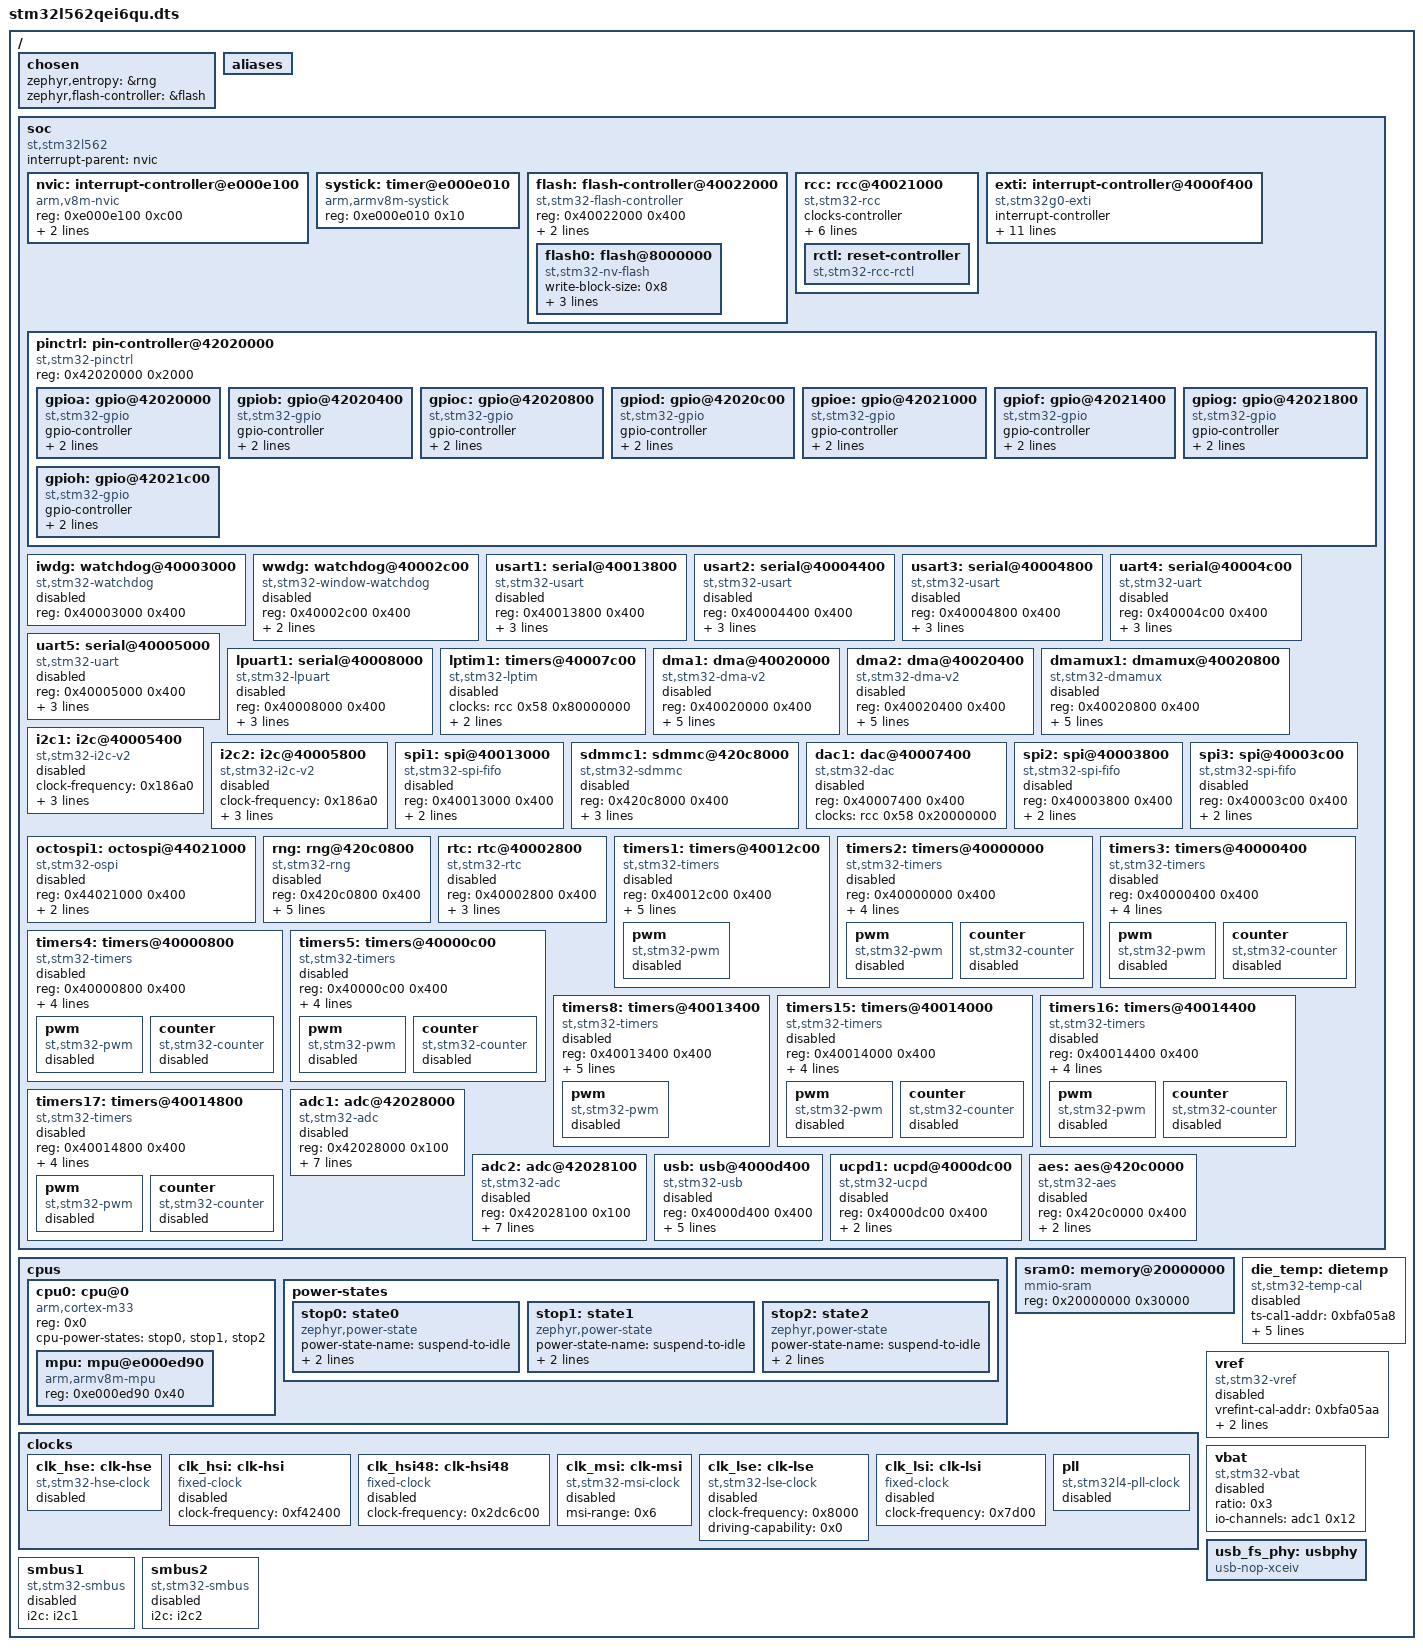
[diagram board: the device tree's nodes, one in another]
/dts-v1/;

/ {
	#address-cells = < 0x1 >;
	#size-cells = < 0x1 >;
	chosen {
		zephyr,entropy = &rng;
		zephyr,flash-controller = &flash;
	};
	aliases {
	};
	soc {
		#address-cells = < 0x1 >;
		#size-cells = < 0x1 >;
		compatible = "st,stm32l562", "st,stm32l5", "simple-bus";
		interrupt-parent = < &nvic >;
		ranges;
		nvic: interrupt-controller@e000e100 {
			#address-cells = < 0x1 >;
			compatible = "arm,v8m-nvic";
			reg = < 0xe000e100 0xc00 >;
			interrupt-controller;
			#interrupt-cells = < 0x2 >;
			arm,num-irq-priority-bits = < 0x3 >;
			phandle = < 0x1 >;
		};
		systick: timer@e000e010 {
			compatible = "arm,armv8m-systick";
			reg = < 0xe000e010 0x10 >;
		};
		flash: flash-controller@40022000 {
			compatible = "st,stm32-flash-controller", "st,stm32l5-flash-controller";
			reg = < 0x40022000 0x400 >;
			interrupts = < 0x6 0x0 >;
			clocks = < &rcc 0x48 0x100 >;
			#address-cells = < 0x1 >;
			#size-cells = < 0x1 >;
			flash0: flash@8000000 {
				compatible = "st,stm32-nv-flash", "soc-nv-flash";
				write-block-size = < 0x8 >;
				erase-block-size = < 0x800 >;
				max-erase-time = < 0x19 >;
				reg = < 0x8000000 0x80000 >;
			};
		};
		rcc: rcc@40021000 {
			compatible = "st,stm32-rcc";
			clocks-controller;
			#clock-cells = < 0x2 >;
			reg = < 0x40021000 0x400 >;
			undershoot-prevention;
			clock-frequency = < 0x1 >;
			ahb-prescaler = < 0x1 >;
			apb1-prescaler = < 0x1 >;
			apb2-prescaler = < 0x1 >;
			phandle = < 0x2 >;
			rctl: reset-controller {
				compatible = "st,stm32-rcc-rctl";
				#reset-cells = < 0x1 >;
				phandle = < 0x3 >;
			};
		};
		exti: interrupt-controller@4000f400 {
			compatible = "st,stm32g0-exti", "st,stm32-exti";
			interrupt-controller;
			#interrupt-cells = < 0x1 >;
			reg = < 0x4000f400 0x400 >;
			num-lines = < 0x10 >;
			interrupts = < 0xb 0x0 >, < 0xc 0x0 >, < 0xd 0x0 >, < 0xe 0x0 >, < 0xf 0x0 >, < 0x10 0x0 >, < 0x11 0x0 >, < 0x12 0x0 >, < 0x13 0x0 >, < 0x14 0x0 >, < 0x15 0x0 >, < 0x16 0x0 >, < 0x17 0x0 >, < 0x18 0x0 >, < 0x19 0x0 >, < 0x1a 0x0 >;
			interrupt-names = "line0", "line1", "line2", "line3", "line4", "line5", "line6", "line7", "line8", "line9", "line10", "line11", "line12", "line13", "line14", "line15";
			line-ranges = < 0x0 0x1 >, < 0x1 0x1 >, < 0x2 0x1 >, < 0x3 0x1 >, < 0x4 0x1 >, < 0x5 0x1 >, < 0x6 0x1 >, < 0x7 0x1 >, < 0x8 0x1 >, < 0x9 0x1 >, < 0xa 0x1 >, < 0xb 0x1 >, < 0xc 0x1 >, < 0xd 0x1 >, < 0xe 0x1 >, < 0xf 0x1 >;
		};
		pinctrl: pin-controller@42020000 {
			compatible = "st,stm32-pinctrl";
			#address-cells = < 0x1 >;
			#size-cells = < 0x1 >;
			reg = < 0x42020000 0x2000 >;
			gpioa: gpio@42020000 {
				compatible = "st,stm32-gpio";
				gpio-controller;
				#gpio-cells = < 0x2 >;
				reg = < 0x42020000 0x400 >;
				clocks = < &rcc 0x4c 0x1 >;
			};
			gpiob: gpio@42020400 {
				compatible = "st,stm32-gpio";
				gpio-controller;
				#gpio-cells = < 0x2 >;
				reg = < 0x42020400 0x400 >;
				clocks = < &rcc 0x4c 0x2 >;
			};
			gpioc: gpio@42020800 {
				compatible = "st,stm32-gpio";
				gpio-controller;
				#gpio-cells = < 0x2 >;
				reg = < 0x42020800 0x400 >;
				clocks = < &rcc 0x4c 0x4 >;
			};
			gpiod: gpio@42020c00 {
				compatible = "st,stm32-gpio";
				gpio-controller;
				#gpio-cells = < 0x2 >;
				reg = < 0x42020c00 0x400 >;
				clocks = < &rcc 0x4c 0x8 >;
			};
			gpioe: gpio@42021000 {
				compatible = "st,stm32-gpio";
				gpio-controller;
				#gpio-cells = < 0x2 >;
				reg = < 0x42021000 0x400 >;
				clocks = < &rcc 0x4c 0x10 >;
			};
			gpiof: gpio@42021400 {
				compatible = "st,stm32-gpio";
				gpio-controller;
				#gpio-cells = < 0x2 >;
				reg = < 0x42021400 0x400 >;
				clocks = < &rcc 0x4c 0x20 >;
			};
			gpiog: gpio@42021800 {
				compatible = "st,stm32-gpio";
				gpio-controller;
				#gpio-cells = < 0x2 >;
				reg = < 0x42021800 0x400 >;
				clocks = < &rcc 0x4c 0x40 >;
			};
			gpioh: gpio@42021c00 {
				compatible = "st,stm32-gpio";
				gpio-controller;
				#gpio-cells = < 0x2 >;
				reg = < 0x42021c00 0x400 >;
				clocks = < &rcc 0x4c 0x80 >;
			};
		};
		iwdg: watchdog@40003000 {
			compatible = "st,stm32-watchdog";
			reg = < 0x40003000 0x400 >;
			status = "disabled";
		};
		wwdg: watchdog@40002c00 {
			compatible = "st,stm32-window-watchdog";
			reg = < 0x40002c00 0x400 >;
			clocks = < &rcc 0x58 0x800 >;
			interrupts = < 0x0 0x6 >;
			status = "disabled";
		};
		usart1: serial@40013800 {
			compatible = "st,stm32-usart", "st,stm32-uart";
			reg = < 0x40013800 0x400 >;
			clocks = < &rcc 0x60 0x4000 >;
			resets = < &rctl 0x80e >;
			interrupts = < 0x3d 0x0 >;
			status = "disabled";
		};
		usart2: serial@40004400 {
			compatible = "st,stm32-usart", "st,stm32-uart";
			reg = < 0x40004400 0x400 >;
			clocks = < &rcc 0x58 0x20000 >;
			resets = < &rctl 0x711 >;
			interrupts = < 0x3e 0x0 >;
			status = "disabled";
		};
		usart3: serial@40004800 {
			compatible = "st,stm32-usart", "st,stm32-uart";
			reg = < 0x40004800 0x400 >;
			clocks = < &rcc 0x58 0x40000 >;
			resets = < &rctl 0x712 >;
			interrupts = < 0x3f 0x0 >;
			status = "disabled";
		};
		uart4: serial@40004c00 {
			compatible = "st,stm32-uart";
			reg = < 0x40004c00 0x400 >;
			clocks = < &rcc 0x58 0x80000 >;
			resets = < &rctl 0x713 >;
			interrupts = < 0x40 0x0 >;
			status = "disabled";
		};
		uart5: serial@40005000 {
			compatible = "st,stm32-uart";
			reg = < 0x40005000 0x400 >;
			clocks = < &rcc 0x58 0x100000 >;
			resets = < &rctl 0x714 >;
			interrupts = < 0x41 0x0 >;
			status = "disabled";
		};
		lpuart1: serial@40008000 {
			compatible = "st,stm32-lpuart", "st,stm32-uart";
			reg = < 0x40008000 0x400 >;
			clocks = < &rcc 0x5c 0x1 >;
			resets = < &rctl 0x780 >;
			interrupts = < 0x42 0x0 >;
			status = "disabled";
		};
		lptim1: timers@40007c00 {
			compatible = "st,stm32-lptim";
			clocks = < &rcc 0x58 0x80000000 >;
			#address-cells = < 0x1 >;
			#size-cells = < 0x0 >;
			reg = < 0x40007c00 0x400 >;
			interrupts = < 0x43 0x1 >;
			interrupt-names = "wakeup";
			status = "disabled";
		};
		dma1: dma@40020000 {
			compatible = "st,stm32-dma-v2";
			#dma-cells = < 0x3 >;
			reg = < 0x40020000 0x400 >;
			interrupts = < 0x1d 0x0 0x1e 0x0 0x1f 0x0 0x20 0x0 0x21 0x0 0x22 0x0 0x23 0x0 0x24 0x0 >;
			clocks = < &rcc 0x48 0x1 >;
			dma-requests = < 0x8 >;
			dma-offset = < 0x0 >;
			status = "disabled";
		};
		dma2: dma@40020400 {
			compatible = "st,stm32-dma-v2";
			#dma-cells = < 0x3 >;
			reg = < 0x40020400 0x400 >;
			interrupts = < 0x50 0x0 0x51 0x0 0x52 0x0 0x53 0x0 0x54 0x0 0x55 0x0 0x56 0x0 0x57 0x0 >;
			clocks = < &rcc 0x48 0x2 >;
			dma-requests = < 0x8 >;
			dma-offset = < 0x8 >;
			status = "disabled";
		};
		dmamux1: dmamux@40020800 {
			compatible = "st,stm32-dmamux";
			#dma-cells = < 0x3 >;
			reg = < 0x40020800 0x400 >;
			interrupts = < 0x1b 0x0 >;
			clocks = < &rcc 0x48 0x4 >;
			dma-channels = < 0x10 >;
			dma-generators = < 0x4 >;
			dma-requests = < 0x5a >;
			status = "disabled";
		};
		i2c1: i2c@40005400 {
			compatible = "st,stm32-i2c-v2";
			clock-frequency = < 0x186a0 >;
			#address-cells = < 0x1 >;
			#size-cells = < 0x0 >;
			reg = < 0x40005400 0x400 >;
			clocks = < &rcc 0x58 0x200000 >;
			interrupts = < 0x37 0x0 >, < 0x38 0x0 >;
			interrupt-names = "event", "error";
			status = "disabled";
			phandle = < 0x9 >;
		};
		i2c2: i2c@40005800 {
			compatible = "st,stm32-i2c-v2";
			#address-cells = < 0x1 >;
			#size-cells = < 0x0 >;
			clock-frequency = < 0x186a0 >;
			reg = < 0x40005800 0x400 >;
			clocks = < &rcc 0x58 0x400000 >;
			interrupts = < 0x39 0x0 >, < 0x3a 0x0 >;
			interrupt-names = "event", "error";
			status = "disabled";
			phandle = < 0xa >;
		};
		spi1: spi@40013000 {
			compatible = "st,stm32-spi-fifo", "st,stm32-spi";
			#address-cells = < 0x1 >;
			#size-cells = < 0x0 >;
			reg = < 0x40013000 0x400 >;
			interrupts = < 0x3b 0x5 >;
			clocks = < &rcc 0x60 0x1000 >;
			status = "disabled";
		};
		sdmmc1: sdmmc@420c8000 {
			compatible = "st,stm32-sdmmc";
			reg = < 0x420c8000 0x400 >;
			clocks = < &rcc 0x4c 0x400000 >, < &rcc 0x2 0x2e9c >;
			resets = < &rctl 0x596 >;
			interrupts = < 0x4e 0x0 >;
			status = "disabled";
		};
		dac1: dac@40007400 {
			compatible = "st,stm32-dac";
			reg = < 0x40007400 0x400 >;
			clocks = < &rcc 0x58 0x20000000 >;
			status = "disabled";
			#io-channel-cells = < 0x1 >;
		};
		spi2: spi@40003800 {
			compatible = "st,stm32-spi-fifo", "st,stm32-spi";
			#address-cells = < 0x1 >;
			#size-cells = < 0x0 >;
			reg = < 0x40003800 0x400 >;
			interrupts = < 0x3c 0x5 >;
			clocks = < &rcc 0x58 0x4000 >;
			status = "disabled";
		};
		spi3: spi@40003c00 {
			compatible = "st,stm32-spi-fifo", "st,stm32-spi";
			#address-cells = < 0x1 >;
			#size-cells = < 0x0 >;
			reg = < 0x40003c00 0x400 >;
			interrupts = < 0x63 0x5 >;
			clocks = < &rcc 0x58 0x8000 >;
			status = "disabled";
		};
		octospi1: octospi@44021000 {
			compatible = "st,stm32-ospi";
			reg = < 0x44021000 0x400 >;
			interrupts = < 0x4c 0x0 >;
			clock-names = "ospix", "ospi-ker";
			clocks = < &rcc 0x50 0x100 >, < &rcc 0x6 0x749c >;
			#address-cells = < 0x1 >;
			#size-cells = < 0x0 >;
			status = "disabled";
		};
		rng: rng@420c0800 {
			compatible = "st,stm32-rng";
			reg = < 0x420c0800 0x400 >;
			interrupts = < 0x5e 0x0 >;
			clocks = < &rcc 0x4c 0x40000 >;
			nist-config = < 0xf00d00 >;
			health-test-magic = < 0x17590abc >;
			health-test-config = < 0xa2b3 >;
			status = "disabled";
		};
		rtc: rtc@40002800 {
			compatible = "st,stm32-rtc";
			reg = < 0x40002800 0x400 >;
			interrupts = < 0x2 0x0 >;
			clocks = < &rcc 0x58 0x400 >;
			prescaler = < 0x8000 >;
			status = "disabled";
		};
		timers1: timers@40012c00 {
			compatible = "st,stm32-timers";
			reg = < 0x40012c00 0x400 >;
			clocks = < &rcc 0x60 0x800 >;
			resets = < &rctl 0x80b >;
			interrupts = < 0x29 0x0 >, < 0x2a 0x0 >, < 0x2b 0x0 >, < 0x2c 0x0 >;
			interrupt-names = "brk", "up", "trgcom", "cc";
			st,prescaler = < 0x0 >;
			status = "disabled";
			pwm {
				compatible = "st,stm32-pwm";
				status = "disabled";
				#pwm-cells = < 0x3 >;
			};
		};
		timers2: timers@40000000 {
			compatible = "st,stm32-timers";
			reg = < 0x40000000 0x400 >;
			clocks = < &rcc 0x58 0x1 >;
			resets = < &rctl 0x700 >;
			interrupts = < 0x2d 0x0 >;
			interrupt-names = "global";
			st,prescaler = < 0x0 >;
			status = "disabled";
			pwm {
				compatible = "st,stm32-pwm";
				status = "disabled";
				#pwm-cells = < 0x3 >;
			};
			counter {
				compatible = "st,stm32-counter";
				status = "disabled";
			};
		};
		timers3: timers@40000400 {
			compatible = "st,stm32-timers";
			reg = < 0x40000400 0x400 >;
			clocks = < &rcc 0x58 0x2 >;
			resets = < &rctl 0x701 >;
			interrupts = < 0x2e 0x0 >;
			interrupt-names = "global";
			st,prescaler = < 0x0 >;
			status = "disabled";
			pwm {
				compatible = "st,stm32-pwm";
				status = "disabled";
				#pwm-cells = < 0x3 >;
			};
			counter {
				compatible = "st,stm32-counter";
				status = "disabled";
			};
		};
		timers4: timers@40000800 {
			compatible = "st,stm32-timers";
			reg = < 0x40000800 0x400 >;
			clocks = < &rcc 0x58 0x4 >;
			resets = < &rctl 0x702 >;
			interrupts = < 0x2f 0x0 >;
			interrupt-names = "global";
			st,prescaler = < 0x0 >;
			status = "disabled";
			pwm {
				compatible = "st,stm32-pwm";
				status = "disabled";
				#pwm-cells = < 0x3 >;
			};
			counter {
				compatible = "st,stm32-counter";
				status = "disabled";
			};
		};
		timers5: timers@40000c00 {
			compatible = "st,stm32-timers";
			reg = < 0x40000c00 0x400 >;
			clocks = < &rcc 0x58 0x8 >;
			resets = < &rctl 0x703 >;
			interrupts = < 0x30 0x0 >;
			interrupt-names = "global";
			st,prescaler = < 0x0 >;
			status = "disabled";
			pwm {
				compatible = "st,stm32-pwm";
				status = "disabled";
				#pwm-cells = < 0x3 >;
			};
			counter {
				compatible = "st,stm32-counter";
				status = "disabled";
			};
		};
		timers8: timers@40013400 {
			compatible = "st,stm32-timers";
			reg = < 0x40013400 0x400 >;
			clocks = < &rcc 0x60 0x2000 >;
			resets = < &rctl 0x80d >;
			interrupts = < 0x33 0x0 >, < 0x34 0x0 >, < 0x35 0x0 >, < 0x36 0x0 >;
			interrupt-names = "brk", "up", "trgcom", "cc";
			st,prescaler = < 0x0 >;
			status = "disabled";
			pwm {
				compatible = "st,stm32-pwm";
				status = "disabled";
				#pwm-cells = < 0x3 >;
			};
		};
		timers15: timers@40014000 {
			compatible = "st,stm32-timers";
			reg = < 0x40014000 0x400 >;
			clocks = < &rcc 0x60 0x10000 >;
			resets = < &rctl 0x810 >;
			interrupts = < 0x45 0x0 >;
			interrupt-names = "global";
			st,prescaler = < 0x0 >;
			status = "disabled";
			pwm {
				compatible = "st,stm32-pwm";
				status = "disabled";
				#pwm-cells = < 0x3 >;
			};
			counter {
				compatible = "st,stm32-counter";
				status = "disabled";
			};
		};
		timers16: timers@40014400 {
			compatible = "st,stm32-timers";
			reg = < 0x40014400 0x400 >;
			clocks = < &rcc 0x60 0x20000 >;
			resets = < &rctl 0x811 >;
			interrupts = < 0x46 0x0 >;
			interrupt-names = "global";
			st,prescaler = < 0x0 >;
			status = "disabled";
			pwm {
				compatible = "st,stm32-pwm";
				status = "disabled";
				#pwm-cells = < 0x3 >;
			};
			counter {
				compatible = "st,stm32-counter";
				status = "disabled";
			};
		};
		timers17: timers@40014800 {
			compatible = "st,stm32-timers";
			reg = < 0x40014800 0x400 >;
			clocks = < &rcc 0x60 0x40000 >;
			resets = < &rctl 0x812 >;
			interrupts = < 0x47 0x0 >;
			interrupt-names = "global";
			st,prescaler = < 0x0 >;
			status = "disabled";
			pwm {
				compatible = "st,stm32-pwm";
				status = "disabled";
				#pwm-cells = < 0x3 >;
			};
			counter {
				compatible = "st,stm32-counter";
				status = "disabled";
			};
		};
		adc1: adc@42028000 {
			compatible = "st,stm32-adc";
			reg = < 0x42028000 0x100 >;
			clocks = < &rcc 0x4c 0x2000 >;
			interrupts = < 0x25 0x0 >;
			status = "disabled";
			#io-channel-cells = < 0x1 >;
			resolutions = < 0x60630c 0x51630c 0x42630c 0x33630c >;
			sampling-times = < 0x3 0x7 0xd 0x19 0x30 0x5d 0xf8 0x281 >;
			st,adc-sequencer = < 0x1 >;
			phandle = < 0x8 >;
		};
		adc2: adc@42028100 {
			compatible = "st,stm32-adc";
			reg = < 0x42028100 0x100 >;
			clocks = < &rcc 0x4c 0x2000 >;
			interrupts = < 0x25 0x0 >;
			status = "disabled";
			#io-channel-cells = < 0x1 >;
			resolutions = < 0x60630c 0x51630c 0x42630c 0x33630c >;
			sampling-times = < 0x3 0x7 0xd 0x19 0x30 0x5d 0xf8 0x281 >;
			st,adc-sequencer = < 0x1 >;
		};
		usb: usb@4000d400 {
			compatible = "st,stm32-usb";
			reg = < 0x4000d400 0x400 >;
			interrupts = < 0x49 0x0 >;
			interrupt-names = "usb";
			num-bidir-endpoints = < 0x8 >;
			ram-size = < 0x400 >;
			status = "disabled";
			clocks = < &rcc 0x5c 0x200000 >, < &rcc 0x2 0x7a88 >;
			phys = < &usb_fs_phy >;
		};
		ucpd1: ucpd@4000dc00 {
			compatible = "st,stm32-ucpd";
			reg = < 0x4000dc00 0x400 >;
			clocks = < &rcc 0x58 0x800000 >;
			interrupts = < 0x6a 0x0 >;
			status = "disabled";
		};
		aes: aes@420c0000 {
			compatible = "st,stm32-aes";
			reg = < 0x420c0000 0x400 >;
			clocks = < &rcc 0x4c 0x10000 >;
			interrupts = < 0x5d 0x0 >;
			status = "disabled";
		};
	};
	cpus {
		#address-cells = < 0x1 >;
		#size-cells = < 0x0 >;
		cpu0: cpu@0 {
			device_type = "cpu";
			compatible = "arm,cortex-m33";
			reg = < 0x0 >;
			#address-cells = < 0x1 >;
			#size-cells = < 0x1 >;
			cpu-power-states = < &stop0 &stop1 &stop2 >;
			mpu: mpu@e000ed90 {
				compatible = "arm,armv8m-mpu";
				reg = < 0xe000ed90 0x40 >;
			};
		};
		power-states {
			stop0: state0 {
				compatible = "zephyr,power-state";
				power-state-name = "suspend-to-idle";
				substate-id = < 0x1 >;
				min-residency-us = < 0x64 >;
				phandle = < 0x5 >;
			};
			stop1: state1 {
				compatible = "zephyr,power-state";
				power-state-name = "suspend-to-idle";
				substate-id = < 0x2 >;
				min-residency-us = < 0x1f4 >;
				phandle = < 0x6 >;
			};
			stop2: state2 {
				compatible = "zephyr,power-state";
				power-state-name = "suspend-to-idle";
				substate-id = < 0x3 >;
				min-residency-us = < 0x384 >;
				phandle = < 0x7 >;
			};
		};
	};
	sram0: memory@20000000 {
		compatible = "mmio-sram";
		reg = < 0x20000000 0x30000 >;
	};
	clocks {
		clk_hse: clk-hse {
			#clock-cells = < 0x0 >;
			compatible = "st,stm32-hse-clock";
			status = "disabled";
		};
		clk_hsi: clk-hsi {
			#clock-cells = < 0x0 >;
			compatible = "fixed-clock";
			clock-frequency = < 0xf42400 >;
			status = "disabled";
		};
		clk_hsi48: clk-hsi48 {
			#clock-cells = < 0x0 >;
			compatible = "fixed-clock";
			clock-frequency = < 0x2dc6c00 >;
			status = "disabled";
		};
		clk_msi: clk-msi {
			#clock-cells = < 0x0 >;
			compatible = "st,stm32-msi-clock";
			msi-range = < 0x6 >;
			status = "disabled";
		};
		clk_lse: clk-lse {
			#clock-cells = < 0x0 >;
			compatible = "st,stm32-lse-clock";
			clock-frequency = < 0x8000 >;
			driving-capability = < 0x0 >;
			status = "disabled";
		};
		clk_lsi: clk-lsi {
			#clock-cells = < 0x0 >;
			compatible = "fixed-clock";
			clock-frequency = < 0x7d00 >;
			status = "disabled";
		};
		pll: pll {
			#clock-cells = < 0x0 >;
			compatible = "st,stm32l4-pll-clock";
			status = "disabled";
		};
	};
	die_temp: dietemp {
		compatible = "st,stm32-temp-cal";
		ts-cal1-addr = < 0xbfa05a8 >;
		ts-cal2-addr = < 0xbfa05ca >;
		ts-cal1-temp = < 0x1e >;
		ts-cal2-temp = < 0x82 >;
		ts-cal-vrefanalog = < 0xbb8 >;
		io-channels = < &adc1 0x11 >;
		status = "disabled";
	};
	vref: vref {
		compatible = "st,stm32-vref";
		vrefint-cal-addr = < 0xbfa05aa >;
		vrefint-cal-mv = < 0xbb8 >;
		io-channels = < &adc1 0x0 >;
		status = "disabled";
	};
	vbat: vbat {
		compatible = "st,stm32-vbat";
		ratio = < 0x3 >;
		io-channels = < &adc1 0x12 >;
		status = "disabled";
	};
	usb_fs_phy: usbphy {
		compatible = "usb-nop-xceiv";
		#phy-cells = < 0x0 >;
		phandle = < 0x4 >;
	};
	smbus1: smbus1 {
		compatible = "st,stm32-smbus";
		#address-cells = < 0x1 >;
		#size-cells = < 0x0 >;
		i2c = < &i2c1 >;
		status = "disabled";
	};
	smbus2: smbus2 {
		compatible = "st,stm32-smbus";
		#address-cells = < 0x1 >;
		#size-cells = < 0x0 >;
		i2c = < &i2c2 >;
		status = "disabled";
	};
};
